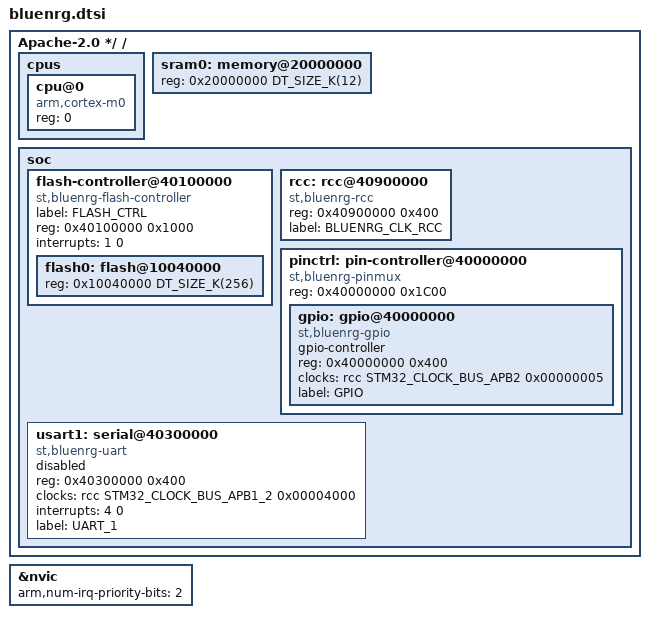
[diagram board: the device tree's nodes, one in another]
*
 * Copyright (c) 2019 Linaro Limited
 * Copyright (c) 2019 Centaur Analytics, Inc
 *
 * SPDX-License-Identifier: Apache-2.0
 */

#include <mem.h>
#include <arm/armv6-m.dtsi>
#include <dt-bindings/gpio/gpio.h>
#include <dt-bindings/i2c/i2c.h>
#include <dt-bindings/clock/stm32_clock.h>

/ {
	cpus {
		#address-cells = <1>;
		#size-cells = <0>;

		cpu@0 {
			device_type = "cpu";
			compatible = "arm,cortex-m0";
			reg = <0>;
		};
	};

	sram0: memory@20000000 {
		device_type = "memory";
		reg = <0x20000000 DT_SIZE_K(12)>;
	};

	soc {
		flash-controller@40100000 {
			compatible = "st,bluenrg-flash-controller";
			label = "FLASH_CTRL";
			reg = <0x40100000 0x1000>;
			interrupts = <1 0>;

			#address-cells = <1>;
			#size-cells = <1>;

			flash0: flash@10040000 {
				reg = <0x10040000 DT_SIZE_K(256)>;
			};
		};

		rcc: rcc@40900000 {
			compatible = "st,bluenrg-rcc";
			#clock-cells = <2>;
			reg = <0x40900000 0x400>;
			label = "BLUENRG_CLK_RCC";
		};

		pinctrl: pin-controller@40000000 {
			compatible = "st,bluenrg-pinmux";
			#address-cells = <1>;
			#size-cells = <1>;
			reg = <0x40000000 0x1C00>;

			gpio: gpio@40000000 {
				compatible = "st,bluenrg-gpio";
				gpio-controller;
				#gpio-cells = <2>;
				reg = <0x40000000 0x400>;
				clocks = <&rcc STM32_CLOCK_BUS_APB2 0x00000005>;
				label = "GPIO";
			};
		};

		usart1: serial@40300000 {
			compatible = "st,bluenrg-uart";
			reg = <0x40300000 0x400>;
			clocks = <&rcc STM32_CLOCK_BUS_APB1_2 0x00004000>;
			interrupts = <4 0>;
			status = "disabled";
			label = "UART_1";
		};
	};
};

&nvic {
	arm,num-irq-priority-bits = <2>;
};
